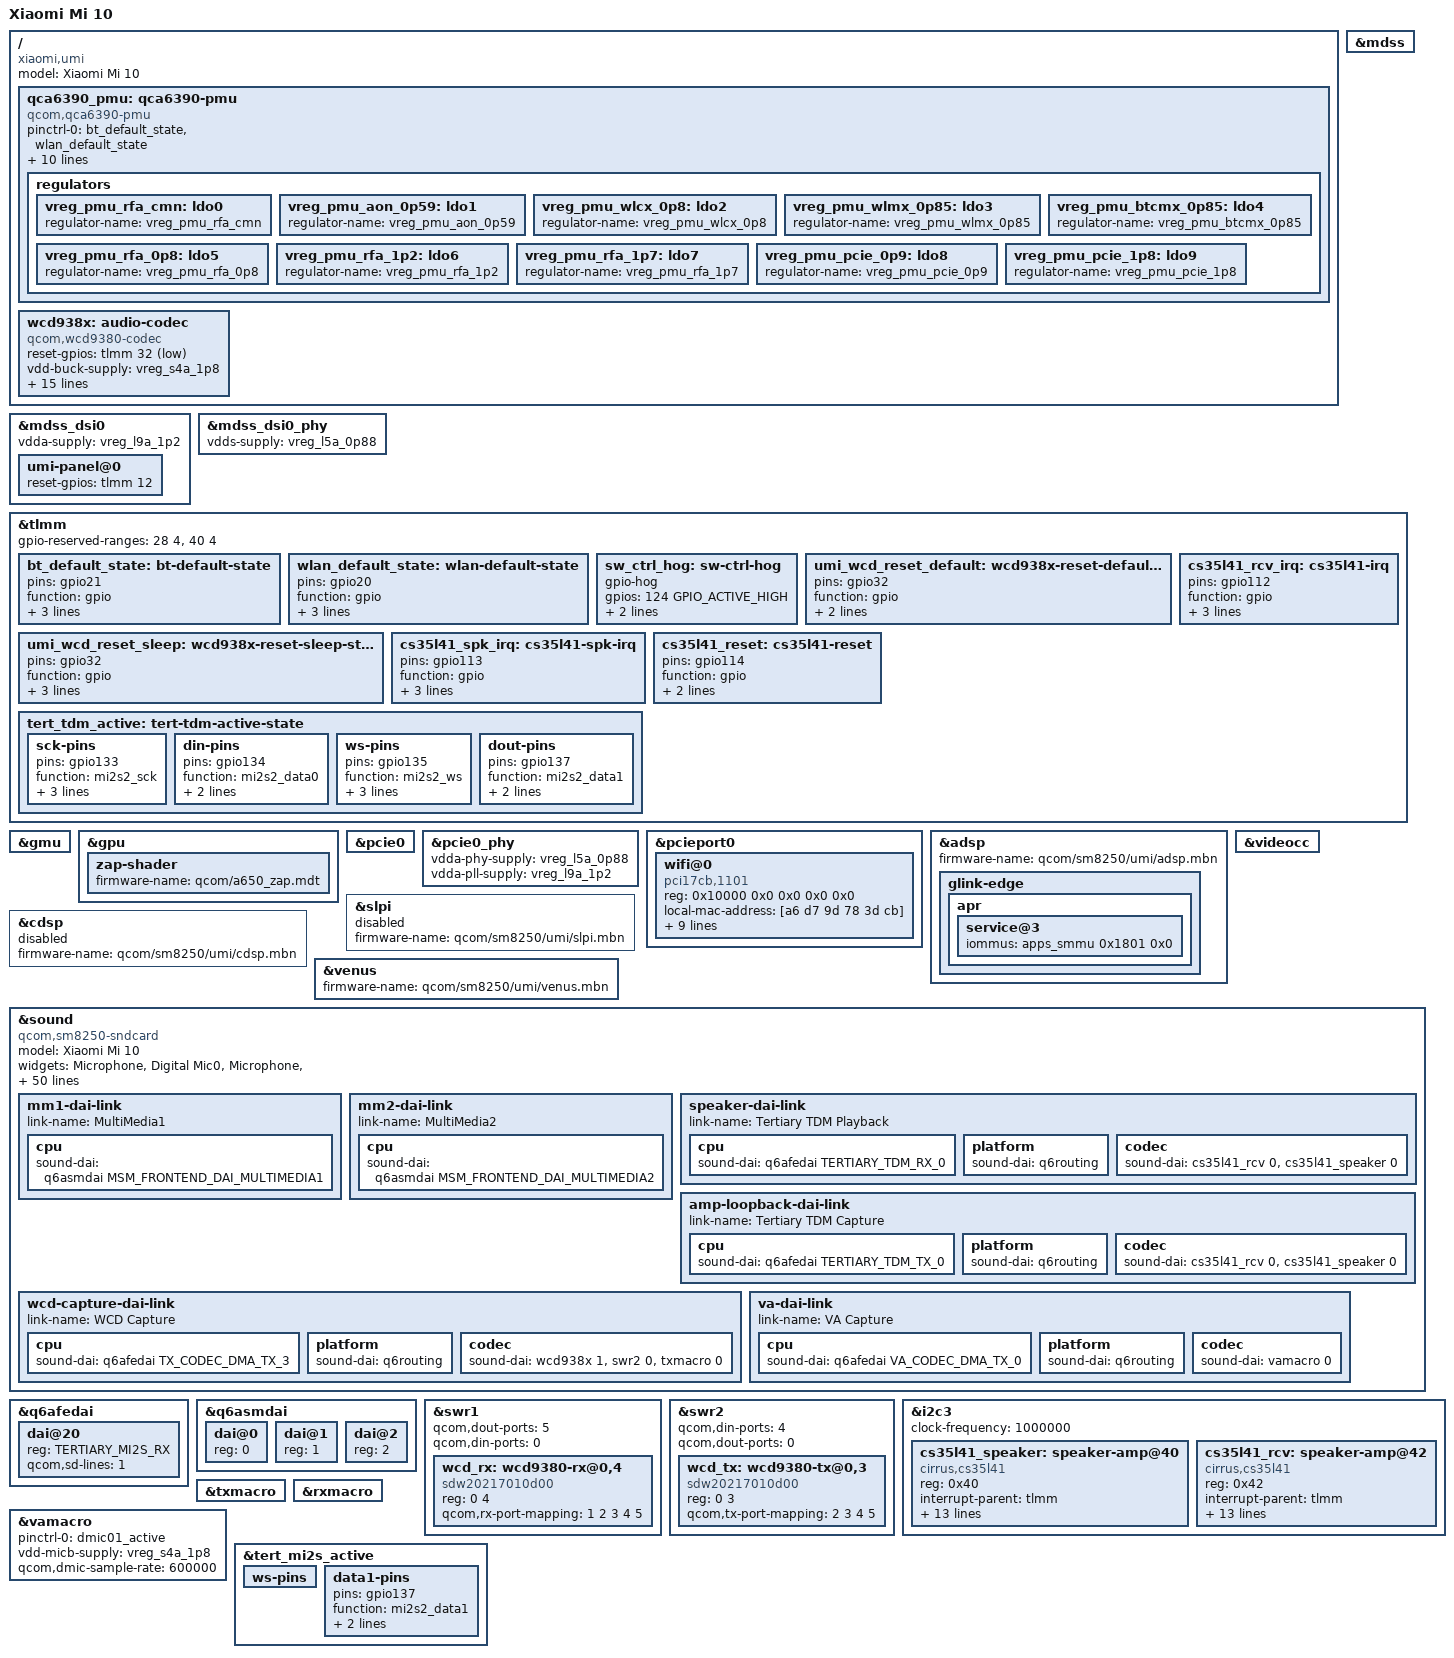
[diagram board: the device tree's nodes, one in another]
// SPDX-License-Identifier: BSD-3-Clause
/*
 * Xiaomi Mi 10 (umi / M2001J2C) — SM8250 "kona" — 板级 DTS（**唯一一份**）
 *
 * ★ 为什么只剩一个文件（2026-11 合并）
 *   以前板级文件有三个：
 *       sm8250-xiaomi-umi.dts       —— 只有显示 + GPU + 半成品 WiFi
 *       sm8250-xiaomi-umi-wifi.dts  —— 显示 + 触摸 + 电池 + QCA6390（真正能用的那颗）
 *       sm8250-xiaomi-umi-plus.dts  —— 早期“进阶外设”试验，PMU 供电压根是错的
 *   于是出现下面这种事故：mkimage.sh 打的是 -wifi.dts，手工跑 pack-umi.py
 *   默认打的是 umi.dts，刷进去之后——没有 WiFi、没有电池、蓝牙连 probe 都不做
 *   （qca6390-pmu 的 pwrseq 只定义在 -wifi.dts 里，而蓝牙要 pwrseq 拉 BT_EN）。
 *
 *   现在只有这一颗 DTB：out/sm8250-xiaomi-umi.dtb，内容 = 板子上的一切。
 *   仍然按功能拆成 .dtsi（common / panels / touch / battery / dtbo-stubs），
 *   那是“一个文件太长”的拆分，**不是**“两个变体”，任何一个 include 都不许漏。
 *
 * 里面每一块的来历、踩过的坑都写在各自的 .dtsi 里，这里只保留板级接线。
 */
/dts-v1/;

#include <dt-bindings/sound/qcom,q6afe.h>
#include <dt-bindings/sound/qcom,q6asm.h>
#include "sm8250-xiaomi-umi-common.dtsi"

/ {
	model = "Xiaomi Mi 10";
	compatible = "xiaomi,umi", "qcom,sm8250";

	/* ------------------------------------------------------------ QCA6390 供电/开关
	 * 供电对应关系以 umi 的下游 DT（qcom,cnss-qca6390）为准：
	 *     vdd-wlan-aon  (.95V) = pm8150_s6   -> vddaon
	 *     vdd-wlan-dig  (.95V) = pm8009_s2   -> vddpmu / vddrfa0p95
	 *     vdd-wlan-io   (1.8V) = pm8150_s4   -> vddio
	 *     vdd-wlan-rfa1 (1.9V) = pm8150_s5   -> vddrfa1p9 / vddpcie1p9
	 *     vdd-wlan-rfa2 (1.35V)= pm8150a_s8  -> vddrfa1p3 / vddpcie1p3
	 *
	 * vddpmu / vddrfa0p95 **不能**接 vreg_s6a_0p95：那是 AON，不是 digital。
	 * 接错的后果是 PM8009 S2 一个 consumer 都没有，regulator_summary 里长期
	 * `vreg_s2f_0p5  0 users  512mV`，QCA6390 的 PMU 数字域没电 —— 卡片在
	 * 总线上永远 Detect.Quiet，WiFi 和蓝牙一起哑。
	 */
	qca6390_pmu: qca6390-pmu {
		compatible = "qcom,qca6390-pmu";

		pinctrl-names = "default";
		pinctrl-0 = <&bt_default_state>, <&wlan_default_state>;

		vddaon-supply = <&vreg_s6a_0p95>;
		vddpmu-supply = <&vreg_s2f_0p95>;
		vddrfa0p95-supply = <&vreg_s2f_0p95>;
		vddrfa1p3-supply = <&vreg_s8c_1p35>;
		vddrfa1p9-supply = <&vreg_s5a_1p9>;
		vddpcie1p3-supply = <&vreg_s8c_1p35>;
		vddpcie1p9-supply = <&vreg_s5a_1p9>;
		vddio-supply = <&vreg_s4a_1p8>;

		/* pwrseq-qcom-wcn 在 probe 时 devm_gpiod_get_optional("wlan-enable"/"bt-enable")
		 * 拿这两条线。**不要**再给它们加 gpio-hog：hog 会独占，pwrseq 拿到
		 * -EBUSY 后设备根本不存在，early power-on 也就永远没人做。 */
		wlan-enable-gpios = <&tlmm 20 GPIO_ACTIVE_HIGH>;
		bt-enable-gpios = <&tlmm 21 GPIO_ACTIVE_HIGH>;

		/* 子节点 ldo0..ldo9：新驱动不消费，但蓝牙节点的 6 条 supply 引用这些
		 * regulator（pwrseq 靠它认 consumer），删了 BT 就起不来。 */
		regulators {
			vreg_pmu_rfa_cmn: ldo0 { regulator-name = "vreg_pmu_rfa_cmn"; };
			vreg_pmu_aon_0p59: ldo1 { regulator-name = "vreg_pmu_aon_0p59"; };
			vreg_pmu_wlcx_0p8: ldo2 { regulator-name = "vreg_pmu_wlcx_0p8"; };
			vreg_pmu_wlmx_0p85: ldo3 { regulator-name = "vreg_pmu_wlmx_0p85"; };
			vreg_pmu_btcmx_0p85: ldo4 { regulator-name = "vreg_pmu_btcmx_0p85"; };
			vreg_pmu_rfa_0p8: ldo5 { regulator-name = "vreg_pmu_rfa_0p8"; };
			vreg_pmu_rfa_1p2: ldo6 { regulator-name = "vreg_pmu_rfa_1p2"; };
			vreg_pmu_rfa_1p7: ldo7 { regulator-name = "vreg_pmu_rfa_1p7"; };
			vreg_pmu_pcie_0p9: ldo8 { regulator-name = "vreg_pmu_pcie_0p9"; };
			vreg_pmu_pcie_1p8: ldo9 { regulator-name = "vreg_pmu_pcie_1p8"; };
		};
	};
};

/* ================================================================= 显示子系统 */
/*
 * 这里**只**给 regulator 的引用，不给任何电压值：
 *   下游 DT：qcom,mdss_dsi_ctrl0 vdda-1p2-supply = pm8150_l9  0x124f80 = 1.2V
 *            qcom,mdss_dsi_phy0  vdda-0p9-supply = pm8150_l5  0xd6d80  = 0.88V
 *   本 DT：  vreg_l9a_1p2 min=max=1200000 ✓ / vreg_l5a_0p88 min=max=880000 ✓
 * 两路轨在下游都是固定值 + proxy-consumer，ABL 起来时就已开着，
 * regulator_enable() 只发 enable，改不了电压。
 */
&mdss {
	status = "okay";
};

&mdss_dsi0 {
	vdda-supply = <&vreg_l9a_1p2>;
	status = "okay";
};

&mdss_dsi0_phy {
	vdds-supply = <&vreg_l5a_0p88>;
	status = "okay";
};

/* 面板：timing / DSC / init 序列全在 DT 里，驱动 patches/panel-xiaomi-umi.c 只读不猜 */
#include "xiaomi-umi-panels.dtsi"

/* 复位脚：下游 qcom,platform-reset-gpio = <&tlmm 0x0c 0x00>（GPIO12，active high）。
 * GPIO12 在 TLMM NORTH tile，common.dtsi 里专门把 gpio-reserved-ranges 拆开把它
 * 留出来（12 单独是可读写的，坏的是别的 pin）。拿不到时驱动退化成“无复位模式”。 */
&mdss_dsi0 {
	umi-panel@0 {
		reset-gpios = <&tlmm 12 GPIO_ACTIVE_HIGH>;
	};
};

/* ================================================================= 触摸 */
#include "sm8250-xiaomi-umi-touch.dtsi"

/* ================================================================= 电量计/充电 */
#include "xiaomi-umi-battery.dtsi"

/* ================================================================= TLMM 保留区
 * 实测：umi 上 TLMM NORTH tile 的寄存器读不了（synchronous external abort）。
 * 之前把整片 NORTH 都 reserved，连 WiFi/BT 使能脚（gpio20/21）和面板复位
 * （gpio12）一起挡了。作者镜像反编译出来的 dtb 只保留 <28 4>、<40 4> 两段，
 * 也就是说 20/21/79/81 全是可用的 —— 这正是他那边 WiFi 能起来的前提。
 * 现在照抄：只留 28-31 / 40-43 两段。
 *
 * ⚠ 绝对不要写“批量探测 NORTH 引脚”的诊断：曾用 copy_from_kernel_nofault
 *   连读 68 个引脚，SError 异步外部中止兜不住 -> panic -> WDT 重启。
 *   要验证某个引脚，就只读那一个。
 */
&tlmm {
	/delete-property/ gpio-reserved-ranges;
	gpio-reserved-ranges = <28 4>, <40 4>;

	/* wlan 是 output-low：上电靠 pwrseq 的 power_on 拉高，不要在这里拉高 */
	bt_default_state: bt-default-state {
		pins = "gpio21";
		function = "gpio";
		drive-strength = <16>;
		output-high;
		bias-pull-up;
	};

	wlan_default_state: wlan-default-state {
		pins = "gpio20";
		function = "gpio";
		drive-strength = <16>;
		output-low;
		bias-pull-up;
	};

	/* 下游 DT 有 qcom,sw-ctrl-gpio = <&tlmm 124>，cnss2 只在链路恢复失败时打印
	 * 它当前电平，从没主动写过。既然 NORTH 可访问了，就当第三道门顺手顶高。 */
	sw_ctrl_hog: sw-ctrl-hog {
		gpio-hog;
		gpios = <124 GPIO_ACTIVE_HIGH>;
		output-high;
		line-name = "sw-ctrl";
	};
};

/* ================================================================= GPU (Adreno 650)
 * 固件（a650_zap.mdt/.b00-.b02、a650_sqe.fw、a650_gmu.bin）必须打进 initramfs：
 * adreno 是内建驱动，probe 发生在 rootfs 挂载之前，只放 /lib/firmware 会 -2。
 * 详见 docs/GPU.md。
 */
&gmu {
	status = "okay";
};

&gpu {
	status = "okay";

	zap-shader {
		firmware-name = "qcom/a650_zap.mdt";
	};
};

/* ============================================================= PCIe0 -> QCA6390
 * 一个属性都不删：pinctrl-0 负责把 pin79/81 的 mux 切到 GPIO 功能，
 * 没有它即使 gpiod 写了值也落不到引脚上（曾经的表现：Phy link never came up）。
 */
&pcie0 {
	status = "okay";
};

&pcie0_phy {
	vdda-phy-supply = <&vreg_l5a_0p88>;
	vdda-pll-supply = <&vreg_l9a_1p2>;
	status = "okay";
};

&pcieport0 {
	wifi@0 {
		compatible = "pci17cb,1101";
		reg = <0x10000 0x0 0x0 0x0 0x0>;

		/* 固定 MAC：不打这个属性时卡片固件每次开机现生成一个。ath11k 在
		 * ath11k_mac_register() 里 device_get_mac_address() 优先取 DT 这个值
		 * （QCA6390 单 radio，pdevs_macaddr_valid 永远 false）。
		 * 换 MAC 只改这一行，然后重打包 boot.img。 */
		local-mac-address = [a6 d7 9d 78 3d cb];

		vddrfacmn-supply = <&vreg_pmu_rfa_cmn>;
		vddaon-supply = <&vreg_pmu_aon_0p59>;
		vddwlcx-supply = <&vreg_pmu_wlcx_0p8>;
		vddwlmx-supply = <&vreg_pmu_wlmx_0p85>;
		vddrfa0p8-supply = <&vreg_pmu_rfa_0p8>;
		vddrfa1p2-supply = <&vreg_pmu_rfa_1p2>;
		vddrfa1p7-supply = <&vreg_pmu_rfa_1p7>;
		vddpcie0p9-supply = <&vreg_pmu_pcie_0p9>;
		vddpcie1p8-supply = <&vreg_pmu_pcie_1p8>;
	};
};

/* 蓝牙节点在 common.dtsi（&uart6 + bluetooth），因为 serial1 alias 必须和
 * uart6 在一起 —— 漏了 alias 会 -ENODEV，没绑上的 uart6 还会把 qnoc 的
 * sync_state() 拖住，pcie0 跟着不 probe，表现就是“蓝牙没起来 WiFi 也没了”。 */

/* ============================================================ 远程处理器
 * ADSP = 音频（Q6AFE/Q6ASM/VA macro），SLPI = 传感器 DSP（SSC，走 fastrpc），
 * CDSP = 计算，Venus = 视频编解码。主线驱动都在，缺的是固件。
 *
 * ★ 固件从 **modem 分区的 image/** 来（不是 dsp 分区，那里只有 DSP 侧 .so）：
 *     /dev/disk/by-partlabel/modem → image/adsp.mdt + image/adsp.b00..b18
 *   装到手机上要改名：
 *     adsp.mdt            -> /lib/firmware/qcom/sm8250/umi/adsp.mbn
 *     adsp.b00 … adsp.b18 -> 同目录原名（qcom_mdt_load 按 .mbn/.mdt 前缀找 bNN）
 *   现成脚本：tools/install-adsp-firmware.sh
 *
 * 目前只开 ADSP（音频的第一块砖）。SLPI/CDSP/Venus 等做到再说，
 * 缺固件时每开一个都会刷一串 -ENOENT。
 */
&adsp {
	status = "okay";
	firmware-name = "qcom/sm8250/umi/adsp.mbn";

	/* AVCS 音频拓扑和 ADSP 的 audio PD 共用 0x1801 这个音频 context bank，
	 * 需要让 glink 上的 APR 总线上报这条 IOMMU 映射，否则拓扑加载失败。
	 * （armbian 0044 里同样的写法；不加这一行，后面做声卡时会卡在这里） */
	glink-edge {
		apr {
			service@3 {
				iommus = <&apps_smmu 0x1801 0x0>;
			};
		};
	};
};

&cdsp {
	firmware-name = "qcom/sm8250/umi/cdsp.mbn";
	status = "disabled";
};

&slpi {
	firmware-name = "qcom/sm8250/umi/slpi.mbn";
	status = "disabled";
};

/* ======================================================= 视频编解码（Venus）
 * 硬件是独立的 Venus 核（SM8250 里叫 video-codec@aa00000），不是 GPU 里的单元：
 *   - 解码：H.264 / HEVC / VP9 / (MPEG2 视固件而定)
 *   - 编码：H.264 / HEVC
 * 主线驱动是三块模块：venus-core / venus-dec / venus-enc，config 里已经有
 * CONFIG_VIDEO_QCOM_VENUS=m。
 *
 * 固件从 modem 分区的 image/ 来（venus.mdt + venus.b00..b19），
 * 装成 /lib/firmware/qcom/sm8250/umi/venus.mbn + venus.bNN
 * （tools/install-venus-firmware.sh）。
 *
 * ★ 还要打开 &videocc：venus 的 core/vcodec0 时钟和 MVS0/MVS0C 两个 GDSC
 *   都由它提供，videocc 关着时 venus probe 会一直 -EPROBE_DEFER。
 * ★ 它的固件要映射到 reserved-memory 里的 video_mem（sm8250.dtsi 已给 5 MB），
 *   我们不要动那块。
 */
&videocc {
	status = "okay";
};

&venus {
	status = "okay";
	firmware-name = "qcom/sm8250/umi/venus.mbn";
};

/* ============================================================ 音频
 *
 * 硬件拓扑（照 armbian 0044 + 厂商 umi-audio-overlay 移植）：
 *
 *   播放：APPS → ADSP(q6asm/q6afe) → TERTIARY TDM(mi2s2 pin: gpio133/134/135/137)
 *         → 两颗 CS35L41（I2C 控制 + TDM 音频）→ 喇叭/听筒
 *   录音：WCD938x（SoundWire swr1/swr2）＋ LPASS VA macro 的 DMIC
 *
 * 板级细节：
 *   - 0x40 那颗 amp 的 sound-name-prefix 是 RCV，接**上**听筒；
 *     0x42 是 LCV，接**下**喇叭。TDM slot 0 = 左声道，所以 dai link 里
 *     先写 cs35l41_rcv（0x42），才能保证"左声道在下面那颗喇叭"。
 *   - 两颗 amp 共用 reset 脚 GPIO114，IRQ 分开：112=LCV，113=RCV。
 *   - WCD938x reset = GPIO32（active low），micbias 必须 2.75V（1.8V 会饿死 AMIC）。
 *   - PD：ADSP 的 avs/audio 需要 pd-mapper 在 userspace 广播，否则声卡不 bind。
 */

/ {
	wcd938x: audio-codec {
		compatible = "qcom,wcd9380-codec";
		status = "okay";
		reset-gpios = <&tlmm 32 GPIO_ACTIVE_LOW>;

		vdd-buck-supply = <&vreg_s4a_1p8>;
		vdd-rxtx-supply = <&vreg_s4a_1p8>;
		vdd-io-supply = <&vreg_s4a_1p8>;
		vdd-mic-bias-supply = <&vreg_bob>;

		/* 2.75 V：厂商 umi-audio-overlay 的 cdc-micbias*-mv 就是这个值；
		 * 用 1.8V 会让 AMIC 没偏置、耳机按键（mbhc）也检测不到 */
		qcom,micbias1-microvolt = <2750000>;
		qcom,micbias2-microvolt = <2750000>;
		qcom,micbias3-microvolt = <2750000>;
		qcom,micbias4-microvolt = <2750000>;
		qcom,mbhc-buttons-vthreshold-microvolt = <75000 150000 237000 500000 500000 500000 500000 500000>;
		qcom,mbhc-headset-vthreshold-microvolt = <1700000>;
		qcom,mbhc-headphone-vthreshold-microvolt = <50000>;
		qcom,rx-device = <&wcd_rx>;
		qcom,tx-device = <&wcd_tx>;

		#sound-dai-cells = <1>;
	};
};

&sound {
	compatible = "qcom,sm8250-sndcard";
	model = "Xiaomi Mi 10";
	widgets =
		"Microphone", "Digital Mic0",
		"Microphone", "Digital Mic1",
		"Microphone", "Digital Mic2",
		"Microphone", "Digital Mic3",
		"Microphone", "Digital Mic4",
		"Microphone", "Digital Mic5";
	audio-routing =
		"AMIC1", "MIC BIAS1",
		"AMIC2", "MIC BIAS2",
		"AMIC3", "MIC BIAS3",
		"AMIC4", "MIC BIAS3",
		"AMIC5", "MIC BIAS4",
		"Digital Mic0", "MIC BIAS3",
		"Digital Mic1", "MIC BIAS3",
		"Digital Mic2", "MIC BIAS1",
		"Digital Mic3", "MIC BIAS1",
		"Digital Mic4", "MIC BIAS4",
		"Digital Mic5", "MIC BIAS4",
		"TX SWR_ADC0", "ADC1_OUTPUT",
		"TX SWR_ADC1", "ADC2_OUTPUT",
		"TX SWR_ADC2", "ADC3_OUTPUT",
		"TX SWR_ADC3", "ADC4_OUTPUT",
		"DMIC1 Pin", "MIC BIAS3",
		"DMIC2 Pin", "MIC BIAS3",
		"DMIC3 Pin", "MIC BIAS1",
		"DMIC4 Pin", "MIC BIAS1",
		"DMIC5 Pin", "MIC BIAS4",
		"DMIC6 Pin", "MIC BIAS4",
		"TX SWR_DMIC0", "DMIC1_OUTPUT",
		"TX SWR_DMIC1", "DMIC2_OUTPUT",
		"TX SWR_DMIC2", "DMIC3_OUTPUT",
		"TX SWR_DMIC3", "DMIC4_OUTPUT",
		"TX SWR_DMIC4", "DMIC5_OUTPUT",
		"TX SWR_DMIC5", "DMIC6_OUTPUT",
		"TX SWR_DMIC6", "DMIC7_OUTPUT",
		"TX SWR_DMIC7", "DMIC8_OUTPUT",
		"VA_AIF1 CAP", "VA_SWR_CLK",
		"VA_AIF2 CAP", "VA_SWR_CLK",
		"VA_AIF3 CAP", "VA_SWR_CLK",
		"Digital Mic0", "VA MIC BIAS3",
		"Digital Mic1", "VA MIC BIAS3",
		"Digital Mic2", "VA MIC BIAS1",
		"Digital Mic3", "VA MIC BIAS1",
		"Digital Mic4", "VA MIC BIAS4",
		"Digital Mic5", "VA MIC BIAS4",
		"DMIC0 Pin", "Digital Mic0",
		"DMIC1 Pin", "Digital Mic1",
		"DMIC2 Pin", "Digital Mic2",
		"DMIC3 Pin", "Digital Mic3",
		"DMIC4 Pin", "Digital Mic4",
		"DMIC5 Pin", "Digital Mic5",
		"VA DMIC0", "VA MIC BIAS3",
		"VA DMIC1", "VA MIC BIAS3",
		"VA DMIC2", "VA MIC BIAS1",
		"VA DMIC3", "VA MIC BIAS1",
		"VA DMIC4", "VA MIC BIAS4",
		"VA DMIC5", "VA MIC BIAS4",
		"VA SWR_ADC0", "VA_SWR_CLK",
		"VA SWR_ADC0", "ADC1_OUTPUT",
		"VA SWR_ADC1", "ADC2_OUTPUT",
		"VA SWR_ADC2", "ADC3_OUTPUT",
		"VA SWR_ADC3", "ADC4_OUTPUT",
		"VA SWR_MIC0", "VA_SWR_CLK",
		"VA SWR_MIC1", "VA_SWR_CLK",
		"VA SWR_MIC2", "VA_SWR_CLK",
		"VA SWR_MIC3", "VA_SWR_CLK",
		"VA SWR_MIC4", "VA_SWR_CLK",
		"VA SWR_MIC5", "VA_SWR_CLK",
		"VA SWR_MIC6", "VA_SWR_CLK",
		"VA SWR_MIC7", "VA_SWR_CLK",
		"VA SWR_MIC0", "DMIC1_OUTPUT",
		"VA SWR_MIC1", "DMIC2_OUTPUT",
		"VA SWR_MIC2", "DMIC3_OUTPUT",
		"VA SWR_MIC3", "DMIC4_OUTPUT",
		"VA SWR_MIC4", "DMIC5_OUTPUT",
		"VA SWR_MIC5", "DMIC6_OUTPUT",
		"VA SWR_MIC6", "DMIC7_OUTPUT",
		"VA SWR_MIC7", "DMIC8_OUTPUT";
	pinctrl-names = "default";
	pinctrl-0 = <&tert_tdm_active>;

	mm1-dai-link {
		link-name = "MultiMedia1";
		cpu {
			sound-dai = <&q6asmdai MSM_FRONTEND_DAI_MULTIMEDIA1>;
		};
	};

	mm2-dai-link {
		link-name = "MultiMedia2";
		cpu {
			sound-dai = <&q6asmdai MSM_FRONTEND_DAI_MULTIMEDIA2>;
		};
	};

	/* 喇叭 + 听筒：Tertiary TDM（mi2s2 引脚） */
	speaker-dai-link {
		link-name = "Tertiary TDM Playback";
		cpu {
			sound-dai = <&q6afedai TERTIARY_TDM_RX_0>;
		};

		platform {
			sound-dai = <&q6routing>;
		};

		codec {
			sound-dai = <&cs35l41_rcv 0>, <&cs35l41_speaker 0>;
		};
	};

	/* 回采：amp 把处理后的输出回灌到 ASP TX（通话 AEC 用） */
	amp-loopback-dai-link {
		link-name = "Tertiary TDM Capture";
		cpu {
			sound-dai = <&q6afedai TERTIARY_TDM_TX_0>;
		};

		platform {
			sound-dai = <&q6routing>;
		};

		codec {
			sound-dai = <&cs35l41_rcv 0>, <&cs35l41_speaker 0>;
		};
	};

	wcd-capture-dai-link {
		link-name = "WCD Capture";
		cpu {
			sound-dai = <&q6afedai TX_CODEC_DMA_TX_3>;
		};

		platform {
			sound-dai = <&q6routing>;
		};

		codec {
			sound-dai = <&wcd938x 1>, <&swr2 0>, <&txmacro 0>;
		};
	};

	va-dai-link {
		link-name = "VA Capture";
		cpu {
			sound-dai = <&q6afedai VA_CODEC_DMA_TX_0>;
		};

		platform {
			sound-dai = <&q6routing>;
		};

		codec {
			sound-dai = <&vamacro 0>;
		};
	};
};

&q6afedai {
	dai@20 {
		reg = <TERTIARY_MI2S_RX>;
		qcom,sd-lines = <1>;
	};
};

&q6asmdai {
	dai@0 {
		reg = <0>;
	};

	dai@1 {
		reg = <1>;
	};

	dai@2 {
		reg = <2>;
	};
};

/* SoundWire：swr1 是 RX（播放侧），swr2 是 TX（录音侧） */
&swr1 {
	status = "okay";
	qcom,dout-ports = <5>;
	qcom,din-ports = <0>;

	wcd_rx: wcd9380-rx@0,4 {
		compatible = "sdw20217010d00";
		reg = <0 4>;
		qcom,rx-port-mapping = <1 2 3 4 5>;
	};
};

&swr2 {
	status = "okay";
	qcom,din-ports = <4>;
	qcom,dout-ports = <0>;

	wcd_tx: wcd9380-tx@0,3 {
		compatible = "sdw20217010d00";
		reg = <0 3>;
		qcom,tx-port-mapping = <2 3 4 5>;
	};
};

/* 两颗 CS35L41 功放 */
&i2c3 {
	status = "okay";
	clock-frequency = <1000000>;

	cs35l41_speaker: speaker-amp@40 {
		compatible = "cirrus,cs35l41";
		status = "okay";
		reg = <0x40>;
		interrupt-parent = <&tlmm>;
		interrupts = <113 IRQ_TYPE_LEVEL_LOW>;
		pinctrl-names = "default";
		pinctrl-0 = <&cs35l41_spk_irq &cs35l41_reset>;
		reset-gpios = <&tlmm 114 GPIO_ACTIVE_HIGH>;
		cirrus,boost-type = <0>;
		cirrus,boost-peak-milliamp = <4000>;
		cirrus,boost-ind-nanohenry = <1000>;
		cirrus,boost-cap-microfarad = <15>;
		cirrus,asp-sdout-hiz = <3>;
		cirrus,gpio2-src-select = <4>;
		cirrus,gpio2-output-enable;
		sound-name-prefix = "RCV";
		VA-supply = <&vreg_s4a_1p8>;
		VP-supply = <&vph_pwr>;
		#sound-dai-cells = <1>;
	};

	cs35l41_rcv: speaker-amp@42 {
		compatible = "cirrus,cs35l41";
		status = "okay";
		reg = <0x42>;
		interrupt-parent = <&tlmm>;
		interrupts = <112 IRQ_TYPE_LEVEL_LOW>;
		pinctrl-names = "default";
		pinctrl-0 = <&cs35l41_rcv_irq>;
		reset-gpios = <&tlmm 114 GPIO_ACTIVE_HIGH>;
		cirrus,boost-type = <0>;
		cirrus,boost-peak-milliamp = <4000>;
		cirrus,boost-ind-nanohenry = <1000>;
		cirrus,boost-cap-microfarad = <15>;
		cirrus,asp-sdout-hiz = <3>;
		cirrus,gpio2-src-select = <4>;
		cirrus,gpio2-output-enable;
		sound-name-prefix = "LCV";
		VA-supply = <&vreg_s4a_1p8>;
		VP-supply = <&vph_pwr>;
		#sound-dai-cells = <1>;
	};
};

&txmacro {
	status = "okay";
};

&rxmacro {
	status = "okay";
};

/* VA macro 负责数字麦采集（VA Capture 那条 link） */
&vamacro {
	pinctrl-names = "default";
	pinctrl-0 = <&dmic01_active>;
	vdd-micb-supply = <&vreg_s4a_1p8>;
	qcom,dmic-sample-rate = <600000>;
};

/* mi2s2 的 pinmux：TDM 用 sck/data0/ws/data1（gpio133/134/135/137） */
&tert_mi2s_active {
	/delete-node/ data0-pins;

	ws-pins {
		/delete-property/ output-high;
	};

	data1-pins {
		pins = "gpio137";
		function = "mi2s2_data1";
		drive-strength = <8>;
		bias-disable;
	};
};

&tlmm {
	umi_wcd_reset_default: wcd938x-reset-default-state {
		pins = "gpio32";
		function = "gpio";
		drive-strength = <16>;
		output-high;
	};

	umi_wcd_reset_sleep: wcd938x-reset-sleep-state {
		pins = "gpio32";
		function = "gpio";
		drive-strength = <16>;
		bias-disable;
		output-low;
	};

	cs35l41_rcv_irq: cs35l41-irq {
		pins = "gpio112";
		function = "gpio";
		drive-strength = <8>;
		bias-pull-up;
		input-enable;
	};

	cs35l41_spk_irq: cs35l41-spk-irq {
		pins = "gpio113";
		function = "gpio";
		drive-strength = <8>;
		bias-pull-up;
		input-enable;
	};

	cs35l41_reset: cs35l41-reset {
		pins = "gpio114";
		function = "gpio";
		drive-strength = <2>;
		bias-disable;
	};

	tert_tdm_active: tert-tdm-active-state {
		sck-pins {
			pins = "gpio133";
			function = "mi2s2_sck";
			drive-strength = <8>;
			bias-disable;
			output-high;
		};

		din-pins {
			pins = "gpio134";
			function = "mi2s2_data0";
			drive-strength = <8>;
			bias-disable;
		};

		ws-pins {
			pins = "gpio135";
			function = "mi2s2_ws";
			drive-strength = <8>;
			bias-disable;
			output-high;
		};

		dout-pins {
			pins = "gpio137";
			function = "mi2s2_data1";
			drive-strength = <8>;
			bias-disable;
		};
	};
};

